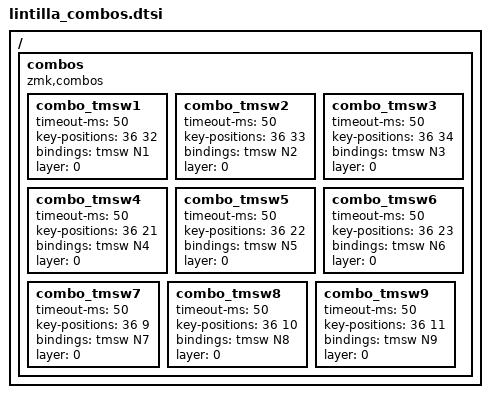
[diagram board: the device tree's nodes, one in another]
//    ┏━━┓                                    ┏━━┓
//    ┃ 0┃                                    ┃ 1┃
// ┏━━╋━━╋━━┳━━┳━━┳━━┓            ┏━━┳━━┳━━┳━━╋━━╋━━┓
// ┃ 2┃ 3┃4 ┃5 ┃ 6┃ 7┃            ┃ 8┃ 9┃10┃11┃12┃13┃
// ┣━━╋━━╋━━╋━━╋━━╋━━┫            ┣━━╋━━╋━━╋━━╋━━╋━━┫
// ┃14┃15┃16┃17┃18┃19┃            ┃20┃21┃22┃23┃24┃25┃
// ┗━━╋━━╋━━╋━━╋━━╋━━┫            ┣━━╋━━╋━━╋━━╋━━╋━━┛
//    ┃26┃27┃28┃29┃30┃            ┃31┃32┃33┃34┃35┃
//    ┗━━┻━━┻━━┻━┳┻━┳┻━┳━━┓  ┏━━┳━┻┳━┻┳━┻━━┻━━┻━━┛
//               ┃36┃37┃38┃  ┃39┃40┃41┃
//               ┗━━┻━━┻━━┛  ┗━━┻━━┻━━┛
/ {
    combos {
        compatible = "zmk,combos";
        combo_tmsw1 {
            timeout-ms = <50>;
            key-positions = <36 32>;
            bindings = <&tmsw N1>;
            layer = <0>;
        };
        combo_tmsw2 {
            timeout-ms = <50>;
            key-positions = <36 33>;
            bindings = <&tmsw N2>;
            layer = <0>;
        };
        combo_tmsw3 {
            timeout-ms = <50>;
            key-positions = <36 34>;
            bindings = <&tmsw N3>;
            layer = <0>;
        };
        combo_tmsw4 {
            timeout-ms = <50>;
            key-positions = <36 21>;
            bindings = <&tmsw N4>;
            layer = <0>;
        };
        combo_tmsw5 {
            timeout-ms = <50>;
            key-positions = <36 22>;
            bindings = <&tmsw N5>;
            layer = <0>;
        };
        combo_tmsw6 {
            timeout-ms = <50>;
            key-positions = <36 23>;
            bindings = <&tmsw N6>;
            layer = <0>;
        };
        combo_tmsw7 {
            timeout-ms = <50>;
            key-positions = <36 9>;
            bindings = <&tmsw N7>;
            layer = <0>;
        };
        combo_tmsw8 {
            timeout-ms = <50>;
            key-positions = <36 10>;
            bindings = <&tmsw N8>;
            layer = <0>;
        };
        combo_tmsw9 {
            timeout-ms = <50>;
            key-positions = <36 11>;
            bindings = <&tmsw N9>;
            layer = <0>;
        };
    };
};

